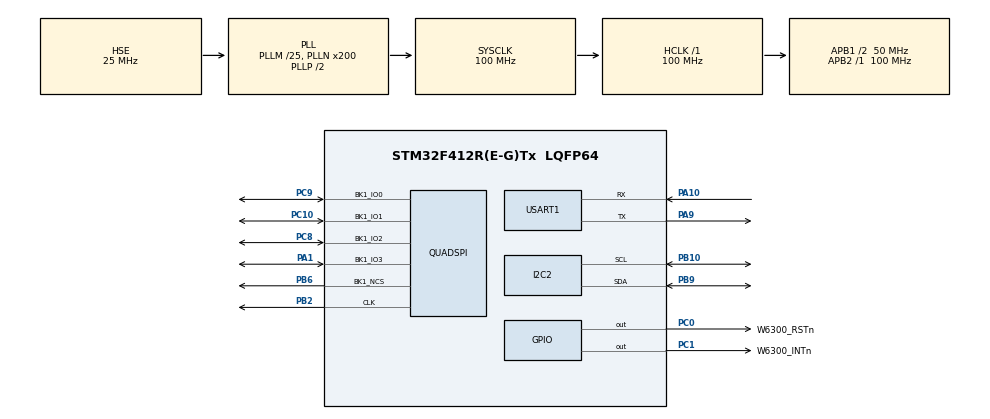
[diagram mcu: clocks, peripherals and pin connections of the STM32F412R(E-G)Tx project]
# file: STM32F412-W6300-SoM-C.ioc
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Dma.QUADSPI.0.Direction=DMA_PERIPH_TO_MEMORY
Dma.QUADSPI.0.FIFOMode=DMA_FIFOMODE_DISABLE
Dma.QUADSPI.0.Instance=DMA2_Stream7
Dma.QUADSPI.0.MemDataAlignment=DMA_MDATAALIGN_BYTE
Dma.QUADSPI.0.MemInc=DMA_MINC_ENABLE
Dma.QUADSPI.0.Mode=DMA_NORMAL
Dma.QUADSPI.0.PeriphDataAlignment=DMA_PDATAALIGN_BYTE
Dma.QUADSPI.0.PeriphInc=DMA_PINC_DISABLE
Dma.QUADSPI.0.Priority=DMA_PRIORITY_HIGH
Dma.Request0=QUADSPI
Mcu.Family=STM32F4
Mcu.Name=STM32F412R(E-G)Tx
Mcu.Package=LQFP64
NVIC.DMA2_Stream7_IRQn=true\:0\:0\:false\:false\:true\:false\:true\:true
NVIC.PriorityGroup=NVIC_PRIORITYGROUP_4
NVIC.QUADSPI_IRQn=true\:0\:0\:false\:false\:true\:true\:true\:true
PA1.Mode=Single Bank 1
PA1.Signal=QUADSPI_BK1_IO3
PA10.Mode=Asynchronous
PA10.Signal=USART1_RX
PA9.Mode=Asynchronous
PA9.Signal=USART1_TX
PB10.GPIO_Pu=GPIO_PULLUP
PB10.Mode=I2C
PB10.Signal=I2C2_SCL
PB2.Mode=Single Bank 1
PB2.Signal=QUADSPI_CLK
PB6.Mode=Single Bank 1
PB6.Signal=QUADSPI_BK1_NCS
PB9.GPIO_Pu=GPIO_PULLUP
PB9.Mode=I2C
PB9.Signal=I2C2_SDA
PC0.GPIO_Label=W6300_RSTn
PC0.Signal=GPIO_Output
PC1.GPIO_Label=W6300_INTn
PC1.Signal=GPIO_Output
PC10.Mode=Single Bank 1
PC10.Signal=QUADSPI_BK1_IO1
PC8.Mode=Single Bank 1
PC8.Signal=QUADSPI_BK1_IO2
PC9.Mode=Single Bank 1
PC9.Signal=QUADSPI_BK1_IO0
PH0\ -\ OSC_IN.Mode=HSE-External-Oscillator
PH0\ -\ OSC_IN.Signal=RCC_OSC_IN
PH1\ -\ OSC_OUT.Mode=HSE-External-Oscillator
PH1\ -\ OSC_OUT.Signal=RCC_OSC_OUT
ProjectManager.HeapSize=0x1000
ProjectManager.StackSize=0x4000
ProjectManager.TargetToolchain=STM32CubeIDE
QUADSPI.ClockPrescaler=1
QUADSPI.FlashSize=24
QUADSPI.SampleShifting=QSPI_SAMPLE_SHIFTING_HALFCYCLE
RCC.AHBFreq_Value=100000000
RCC.APB1CLKDivider=RCC_HCLK_DIV2
RCC.APB1Freq_Value=50000000
RCC.APB1TimFreq_Value=100000000
RCC.APB2Freq_Value=100000000
RCC.APB2TimFreq_Value=100000000
RCC.CortexFreq_Value=100000000
RCC.HCLKFreq_Value=100000000
RCC.HSE_VALUE=25000000
RCC.PLLM=25
RCC.PLLN=200
RCC.PLLSourceVirtual=RCC_PLLSOURCE_HSE
RCC.SYSCLKFreq_VALUE=100000000
RCC.SYSCLKSource=RCC_SYSCLKSOURCE_PLLCLK
RCC.USBFreq_Value=100000000
RCC.VCOOutputFreq_Value=200000000
USART1.VirtualMode=VM_ASYNC
board=custom

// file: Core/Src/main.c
/* USER CODE BEGIN Header */
/**
  ******************************************************************************
  * @file           : main.c
  * @brief          : Main program body
  ******************************************************************************
  * @attention
  *
  * Copyright (c) 2026 STMicroelectronics.
  * All rights reserved.
  *
  * This software is licensed under terms that can be found in the LICENSE file
  * in the root directory of this software component.
  * If no LICENSE file comes with this software, it is provided AS-IS.
  *
  ******************************************************************************
  */
/* USER CODE END Header */
#include "main.h"

/* USER CODE BEGIN Includes */
#include <stdio.h>
#include "app_main.h"
/* USER CODE END Includes */

I2C_HandleTypeDef hi2c2;

QSPI_HandleTypeDef hqspi;
DMA_HandleTypeDef hdma_quadspi;

UART_HandleTypeDef huart1;

void SystemClock_Config(void);
static void MX_GPIO_Init(void);
static void MX_DMA_Init(void);
static void MX_I2C2_Init(void);
static void MX_QUADSPI_Init(void);
static void MX_USART1_UART_Init(void);

/* USER CODE BEGIN 0 */
int __io_putchar(int ch)
{
  HAL_UART_Transmit(&huart1, (uint8_t *)&ch, 1, HAL_MAX_DELAY);
  return ch;
}
/* USER CODE END 0 */

int main(void)
{

  /* MCU Configuration--------------------------------------------------------*/

  /* Reset of all peripherals, Initializes the Flash interface and the Systick. */
  HAL_Init();

  /* Configure the system clock */
  SystemClock_Config();

  /* Initialize all configured peripherals */
  MX_GPIO_Init();
  MX_DMA_Init();
  MX_I2C2_Init();
  MX_QUADSPI_Init();
  MX_USART1_UART_Init();
  /* USER CODE BEGIN 2 */
  app_main();
  /* USER CODE END 2 */

  /* Infinite loop */
  while (1)
  {

  }
}

void SystemClock_Config(void)
{
  RCC_OscInitTypeDef RCC_OscInitStruct = {0};
  RCC_ClkInitTypeDef RCC_ClkInitStruct = {0};

  /** Configure the main internal regulator output voltage
  */
  __HAL_RCC_PWR_CLK_ENABLE();
  __HAL_PWR_VOLTAGESCALING_CONFIG(PWR_REGULATOR_VOLTAGE_SCALE1);

  /** Initializes the RCC Oscillators according to the specified parameters
  * in the RCC_OscInitTypeDef structure.
  */
  RCC_OscInitStruct.OscillatorType = RCC_OSCILLATORTYPE_HSE;
  RCC_OscInitStruct.HSEState = RCC_HSE_ON;
  RCC_OscInitStruct.PLL.PLLState = RCC_PLL_ON;
  RCC_OscInitStruct.PLL.PLLSource = RCC_PLLSOURCE_HSE;
  RCC_OscInitStruct.PLL.PLLM = 25;
  RCC_OscInitStruct.PLL.PLLN = 200;
  RCC_OscInitStruct.PLL.PLLP = RCC_PLLP_DIV2;
  RCC_OscInitStruct.PLL.PLLQ = 2;
  RCC_OscInitStruct.PLL.PLLR = 2;
  if (HAL_RCC_OscConfig(&RCC_OscInitStruct) != HAL_OK)
  {
    Error_Handler();
  }

  /** Initializes the CPU, AHB and APB buses clocks
  */
  RCC_ClkInitStruct.ClockType = RCC_CLOCKTYPE_HCLK|RCC_CLOCKTYPE_SYSCLK
                              |RCC_CLOCKTYPE_PCLK1|RCC_CLOCKTYPE_PCLK2;
  RCC_ClkInitStruct.SYSCLKSource = RCC_SYSCLKSOURCE_PLLCLK;
  RCC_ClkInitStruct.AHBCLKDivider = RCC_SYSCLK_DIV1;
  RCC_ClkInitStruct.APB1CLKDivider = RCC_HCLK_DIV2;
  RCC_ClkInitStruct.APB2CLKDivider = RCC_HCLK_DIV1;

  if (HAL_RCC_ClockConfig(&RCC_ClkInitStruct, FLASH_LATENCY_3) != HAL_OK)
  {
    Error_Handler();
  }
}

static void MX_I2C2_Init(void)
{

  hi2c2.Instance = I2C2;
  hi2c2.Init.ClockSpeed = 100000;
  hi2c2.Init.DutyCycle = I2C_DUTYCYCLE_2;
  hi2c2.Init.OwnAddress1 = 0;
  hi2c2.Init.AddressingMode = I2C_ADDRESSINGMODE_7BIT;
  hi2c2.Init.DualAddressMode = I2C_DUALADDRESS_DISABLE;
  hi2c2.Init.OwnAddress2 = 0;
  hi2c2.Init.GeneralCallMode = I2C_GENERALCALL_DISABLE;
  hi2c2.Init.NoStretchMode = I2C_NOSTRETCH_DISABLE;
  if (HAL_I2C_Init(&hi2c2) != HAL_OK)
  {
    Error_Handler();
  }

}

static void MX_QUADSPI_Init(void)
{

  /* QUADSPI parameter configuration*/
  hqspi.Instance = QUADSPI;
  hqspi.Init.ClockPrescaler = 1;
  hqspi.Init.FifoThreshold = 1;
  hqspi.Init.SampleShifting = QSPI_SAMPLE_SHIFTING_HALFCYCLE;
  hqspi.Init.FlashSize = 24;
  hqspi.Init.ChipSelectHighTime = QSPI_CS_HIGH_TIME_1_CYCLE;
  hqspi.Init.ClockMode = QSPI_CLOCK_MODE_0;
  hqspi.Init.FlashID = QSPI_FLASH_ID_1;
  hqspi.Init.DualFlash = QSPI_DUALFLASH_DISABLE;
  if (HAL_QSPI_Init(&hqspi) != HAL_OK)
  {
    Error_Handler();
  }

}

static void MX_USART1_UART_Init(void)
{

  huart1.Instance = USART1;
  huart1.Init.BaudRate = 115200;
  huart1.Init.WordLength = UART_WORDLENGTH_8B;
  huart1.Init.StopBits = UART_STOPBITS_1;
  huart1.Init.Parity = UART_PARITY_NONE;
  huart1.Init.Mode = UART_MODE_TX_RX;
  huart1.Init.HwFlowCtl = UART_HWCONTROL_NONE;
  huart1.Init.OverSampling = UART_OVERSAMPLING_16;
  if (HAL_UART_Init(&huart1) != HAL_OK)
  {
    Error_Handler();
  }

}

static void MX_DMA_Init(void)
{

  /* DMA controller clock enable */
  __HAL_RCC_DMA2_CLK_ENABLE();

  /* DMA interrupt init */
  /* DMA2_Stream7_IRQn interrupt configuration */
  HAL_NVIC_SetPriority(DMA2_Stream7_IRQn, 0, 0);
  HAL_NVIC_EnableIRQ(DMA2_Stream7_IRQn);

}

static void MX_GPIO_Init(void)
{
  GPIO_InitTypeDef GPIO_InitStruct = {0};

  /* GPIO Ports Clock Enable */
  __HAL_RCC_GPIOH_CLK_ENABLE();
  __HAL_RCC_GPIOC_CLK_ENABLE();
  __HAL_RCC_GPIOA_CLK_ENABLE();
  __HAL_RCC_GPIOB_CLK_ENABLE();

  /*Configure GPIO pin Output Level */
  HAL_GPIO_WritePin(GPIOC, W6300_RSTn_Pin|W6300_INTn_Pin, GPIO_PIN_RESET);

  /*Configure GPIO pins : W6300_RSTn_Pin W6300_INTn_Pin */
  GPIO_InitStruct.Pin = W6300_RSTn_Pin|W6300_INTn_Pin;
  GPIO_InitStruct.Mode = GPIO_MODE_OUTPUT_PP;
  GPIO_InitStruct.Pull = GPIO_NOPULL;
  GPIO_InitStruct.Speed = GPIO_SPEED_FREQ_LOW;
  HAL_GPIO_Init(GPIOC, &GPIO_InitStruct);

}

void Error_Handler(void)
{
  __disable_irq();
  while (1)
  {
  }
}
